AUTOSAR XML (schema 4-0-3)
standard types defined: Boolean, UInt16, UInt8
package /AUTOSAR_Platform/DataConstrs
  range DC_Boolean: raw 0..1
  range DC_UInt16: raw 0..65535
  range DC_UInt8: raw 0..255
package /PATAC/MSM/ComponentTypes
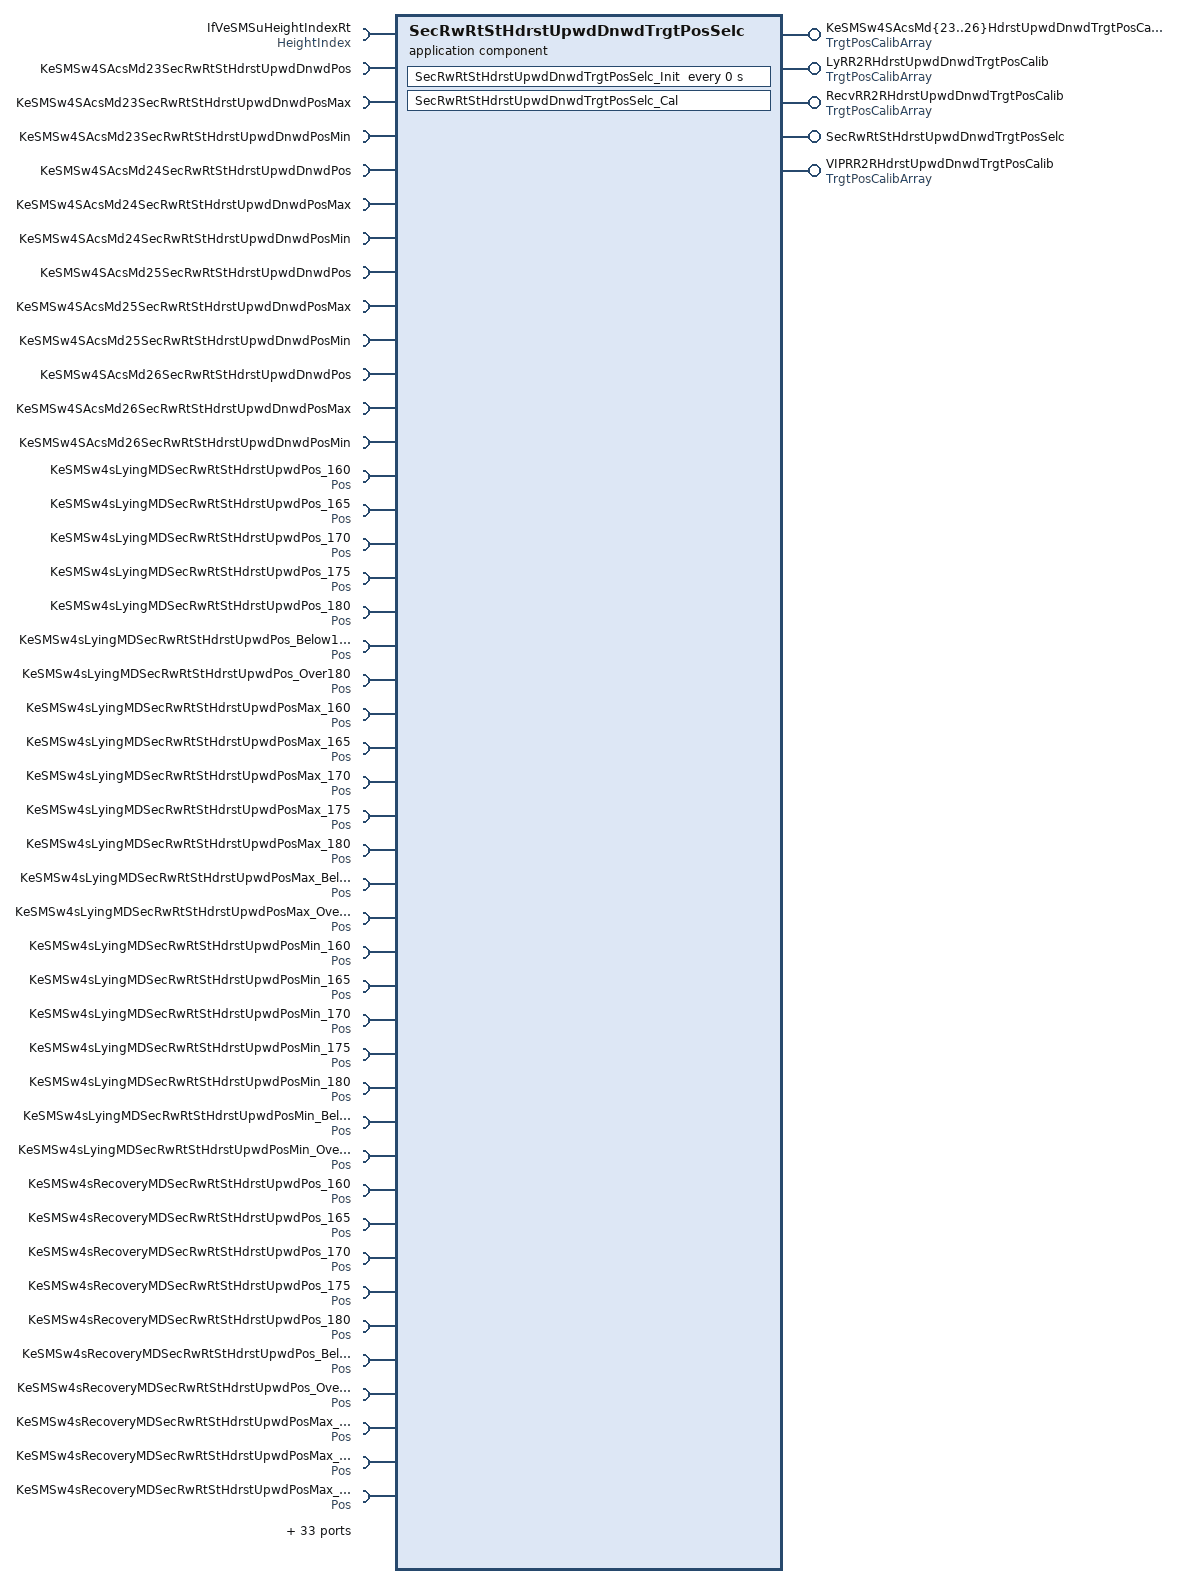
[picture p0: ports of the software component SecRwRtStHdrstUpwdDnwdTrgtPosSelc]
  application sw component type SecRwRtStHdrstUpwdDnwdTrgtPosSelc
    8 x provide port:
      KeSMSw4SAcsMd{23..26}HdrstUpwdDnwdTrgtPosCalib: nonqueued-sender-com-spec{data-element=TrgtPosArray, init-value=[4095, 4095, 4095]}, provided-interface=TrgtPosCalibArray
      LyRR2RHdrstUpwdDnwdTrgtPosCalib: nonqueued-sender-com-spec{data-element=TrgtPosArray, init-value=[4095, 4095, 4095]}, provided-interface=TrgtPosCalibArray
      RecvRR2RHdrstUpwdDnwdTrgtPosCalib: nonqueued-sender-com-spec{data-element=TrgtPosArray, init-value=[4095, 4095, 4095]}, provided-interface=TrgtPosCalibArray
      SecRwRtStHdrstUpwdDnwdTrgtPosSelc: server-com-spec{operation=Cal, queue-length=1}, provided-interface=SecRwRtStHdrstUpwdDnwdTrgtPosSelc
      VIPRR2RHdrstUpwdDnwdTrgtPosCalib: nonqueued-sender-com-spec{data-element=TrgtPosArray, init-value=[4095, 4095, 4095]}, provided-interface=TrgtPosCalibArray
    77 x require port:
      IfVeSMSuHeightIndexRt: nonqueued-receiver-com-spec{data-element=Val, filter=data-filter-type=ALWAYS, init-value=0}, required-interface=HeightIndex
      KeSMSw4SAcsMd23SecRwRtStHdrstUpwdDnwdPos: parameter-require-com-spec{init-value=0, parameter=KeSMSw4SAcsMd23SecRwRtStHdrstUpwdDnwdPos/Val}, required-interface=KeSMSw4SAcsMd23SecRwRtStHdrstUpwdDnwdPos
      KeSMSw4SAcsMd23SecRwRtStHdrstUpwdDnwdPosMax: parameter-require-com-spec{init-value=0, parameter=KeSMSw4SAcsMd23SecRwRtStHdrstUpwdDnwdPosMax/Val}, required-interface=KeSMSw4SAcsMd23SecRwRtStHdrstUpwdDnwdPosMax
      KeSMSw4SAcsMd23SecRwRtStHdrstUpwdDnwdPosMin: parameter-require-com-spec{init-value=0, parameter=KeSMSw4SAcsMd23SecRwRtStHdrstUpwdDnwdPosMin/Val}, required-interface=KeSMSw4SAcsMd23SecRwRtStHdrstUpwdDnwdPosMin
      KeSMSw4SAcsMd24SecRwRtStHdrstUpwdDnwdPos: parameter-require-com-spec{init-value=0, parameter=KeSMSw4SAcsMd24SecRwRtStHdrstUpwdDnwdPos/Val}, required-interface=KeSMSw4SAcsMd24SecRwRtStHdrstUpwdDnwdPos
      KeSMSw4SAcsMd24SecRwRtStHdrstUpwdDnwdPosMax: parameter-require-com-spec{init-value=0, parameter=KeSMSw4SAcsMd24SecRwRtStHdrstUpwdDnwdPosMax/Val}, required-interface=KeSMSw4SAcsMd24SecRwRtStHdrstUpwdDnwdPosMax
      KeSMSw4SAcsMd24SecRwRtStHdrstUpwdDnwdPosMin: parameter-require-com-spec{init-value=0, parameter=KeSMSw4SAcsMd24SecRwRtStHdrstUpwdDnwdPosMin/Val}, required-interface=KeSMSw4SAcsMd24SecRwRtStHdrstUpwdDnwdPosMin
      KeSMSw4SAcsMd25SecRwRtStHdrstUpwdDnwdPos: parameter-require-com-spec{init-value=0, parameter=KeSMSw4SAcsMd25SecRwRtStHdrstUpwdDnwdPos/Val}, required-interface=KeSMSw4SAcsMd25SecRwRtStHdrstUpwdDnwdPos
      KeSMSw4SAcsMd25SecRwRtStHdrstUpwdDnwdPosMax: parameter-require-com-spec{init-value=0, parameter=KeSMSw4SAcsMd25SecRwRtStHdrstUpwdDnwdPosMax/Val}, required-interface=KeSMSw4SAcsMd25SecRwRtStHdrstUpwdDnwdPosMax
      KeSMSw4SAcsMd25SecRwRtStHdrstUpwdDnwdPosMin: parameter-require-com-spec{init-value=0, parameter=KeSMSw4SAcsMd25SecRwRtStHdrstUpwdDnwdPosMin/Val}, required-interface=KeSMSw4SAcsMd25SecRwRtStHdrstUpwdDnwdPosMin
      KeSMSw4SAcsMd26SecRwRtStHdrstUpwdDnwdPos: parameter-require-com-spec{init-value=0, parameter=KeSMSw4SAcsMd26SecRwRtStHdrstUpwdDnwdPos/Val}, required-interface=KeSMSw4SAcsMd26SecRwRtStHdrstUpwdDnwdPos
      KeSMSw4SAcsMd26SecRwRtStHdrstUpwdDnwdPosMax: parameter-require-com-spec{init-value=0, parameter=KeSMSw4SAcsMd26SecRwRtStHdrstUpwdDnwdPosMax/Val}, required-interface=KeSMSw4SAcsMd26SecRwRtStHdrstUpwdDnwdPosMax
      KeSMSw4SAcsMd26SecRwRtStHdrstUpwdDnwdPosMin: parameter-require-com-spec{init-value=0, parameter=KeSMSw4SAcsMd26SecRwRtStHdrstUpwdDnwdPosMin/Val}, required-interface=KeSMSw4SAcsMd26SecRwRtStHdrstUpwdDnwdPosMin
      KeSMSw4sLyingMDSecRwRtStHdrstUpwdPos_160: parameter-require-com-spec{init-value=0, parameter=Pos/Val}, required-interface=Pos
      KeSMSw4sLyingMDSecRwRtStHdrstUpwdPos_165: parameter-require-com-spec{init-value=0, parameter=Pos/Val}, required-interface=Pos
      KeSMSw4sLyingMDSecRwRtStHdrstUpwdPos_170: parameter-require-com-spec{init-value=0, parameter=Pos/Val}, required-interface=Pos
      KeSMSw4sLyingMDSecRwRtStHdrstUpwdPos_175: parameter-require-com-spec{init-value=0, parameter=Pos/Val}, required-interface=Pos
      KeSMSw4sLyingMDSecRwRtStHdrstUpwdPos_180: parameter-require-com-spec{init-value=0, parameter=Pos/Val}, required-interface=Pos
      KeSMSw4sLyingMDSecRwRtStHdrstUpwdPos_Below160: parameter-require-com-spec{init-value=0, parameter=Pos/Val}, required-interface=Pos
      KeSMSw4sLyingMDSecRwRtStHdrstUpwdPos_Over180: parameter-require-com-spec{init-value=0, parameter=Pos/Val}, required-interface=Pos
      KeSMSw4sLyingMDSecRwRtStHdrstUpwdPosMax_160: parameter-require-com-spec{init-value=0, parameter=Pos/Val}, required-interface=Pos
      KeSMSw4sLyingMDSecRwRtStHdrstUpwdPosMax_165: parameter-require-com-spec{init-value=0, parameter=Pos/Val}, required-interface=Pos
      KeSMSw4sLyingMDSecRwRtStHdrstUpwdPosMax_170: parameter-require-com-spec{init-value=0, parameter=Pos/Val}, required-interface=Pos
      KeSMSw4sLyingMDSecRwRtStHdrstUpwdPosMax_175: parameter-require-com-spec{init-value=0, parameter=Pos/Val}, required-interface=Pos
      KeSMSw4sLyingMDSecRwRtStHdrstUpwdPosMax_180: parameter-require-com-spec{init-value=0, parameter=Pos/Val}, required-interface=Pos
      KeSMSw4sLyingMDSecRwRtStHdrstUpwdPosMax_Below160: parameter-require-com-spec{init-value=0, parameter=Pos/Val}, required-interface=Pos
      KeSMSw4sLyingMDSecRwRtStHdrstUpwdPosMax_Over180: parameter-require-com-spec{init-value=0, parameter=Pos/Val}, required-interface=Pos
      KeSMSw4sLyingMDSecRwRtStHdrstUpwdPosMin_160: parameter-require-com-spec{init-value=0, parameter=Pos/Val}, required-interface=Pos
      KeSMSw4sLyingMDSecRwRtStHdrstUpwdPosMin_165: parameter-require-com-spec{init-value=0, parameter=Pos/Val}, required-interface=Pos
      KeSMSw4sLyingMDSecRwRtStHdrstUpwdPosMin_170: parameter-require-com-spec{init-value=0, parameter=Pos/Val}, required-interface=Pos
      KeSMSw4sLyingMDSecRwRtStHdrstUpwdPosMin_175: parameter-require-com-spec{init-value=0, parameter=Pos/Val}, required-interface=Pos
      KeSMSw4sLyingMDSecRwRtStHdrstUpwdPosMin_180: parameter-require-com-spec{init-value=0, parameter=Pos/Val}, required-interface=Pos
      KeSMSw4sLyingMDSecRwRtStHdrstUpwdPosMin_Below160: parameter-require-com-spec{init-value=0, parameter=Pos/Val}, required-interface=Pos
      KeSMSw4sLyingMDSecRwRtStHdrstUpwdPosMin_Over180: parameter-require-com-spec{init-value=0, parameter=Pos/Val}, required-interface=Pos
      KeSMSw4sRecoveryMDSecRwRtStHdrstUpwdPos_160: parameter-require-com-spec{init-value=0, parameter=Pos/Val}, required-interface=Pos
      KeSMSw4sRecoveryMDSecRwRtStHdrstUpwdPos_165: parameter-require-com-spec{init-value=0, parameter=Pos/Val}, required-interface=Pos
      KeSMSw4sRecoveryMDSecRwRtStHdrstUpwdPos_170: parameter-require-com-spec{init-value=0, parameter=Pos/Val}, required-interface=Pos
      KeSMSw4sRecoveryMDSecRwRtStHdrstUpwdPos_175: parameter-require-com-spec{init-value=0, parameter=Pos/Val}, required-interface=Pos
      KeSMSw4sRecoveryMDSecRwRtStHdrstUpwdPos_180: parameter-require-com-spec{init-value=0, parameter=Pos/Val}, required-interface=Pos
      KeSMSw4sRecoveryMDSecRwRtStHdrstUpwdPos_Below160: parameter-require-com-spec{init-value=0, parameter=Pos/Val}, required-interface=Pos
      KeSMSw4sRecoveryMDSecRwRtStHdrstUpwdPos_Over180: parameter-require-com-spec{init-value=0, parameter=Pos/Val}, required-interface=Pos
      KeSMSw4sRecoveryMDSecRwRtStHdrstUpwdPosMax_160: parameter-require-com-spec{init-value=0, parameter=Pos/Val}, required-interface=Pos
      KeSMSw4sRecoveryMDSecRwRtStHdrstUpwdPosMax_165: parameter-require-com-spec{init-value=0, parameter=Pos/Val}, required-interface=Pos
      KeSMSw4sRecoveryMDSecRwRtStHdrstUpwdPosMax_170: parameter-require-com-spec{init-value=0, parameter=Pos/Val}, required-interface=Pos
      KeSMSw4sRecoveryMDSecRwRtStHdrstUpwdPosMax_175: parameter-require-com-spec{init-value=0, parameter=Pos/Val}, required-interface=Pos
      KeSMSw4sRecoveryMDSecRwRtStHdrstUpwdPosMax_180: parameter-require-com-spec{init-value=0, parameter=Pos/Val}, required-interface=Pos
      KeSMSw4sRecoveryMDSecRwRtStHdrstUpwdPosMax_Below160: parameter-require-com-spec{init-value=0, parameter=Pos/Val}, required-interface=Pos
      KeSMSw4sRecoveryMDSecRwRtStHdrstUpwdPosMax_Over180: parameter-require-com-spec{init-value=0, parameter=Pos/Val}, required-interface=Pos
      KeSMSw4sRecoveryMDSecRwRtStHdrstUpwdPosMin_160: parameter-require-com-spec{init-value=0, parameter=Pos/Val}, required-interface=Pos
      KeSMSw4sRecoveryMDSecRwRtStHdrstUpwdPosMin_165: parameter-require-com-spec{init-value=0, parameter=Pos/Val}, required-interface=Pos
      KeSMSw4sRecoveryMDSecRwRtStHdrstUpwdPosMin_170: parameter-require-com-spec{init-value=0, parameter=Pos/Val}, required-interface=Pos
      KeSMSw4sRecoveryMDSecRwRtStHdrstUpwdPosMin_175: parameter-require-com-spec{init-value=0, parameter=Pos/Val}, required-interface=Pos
      KeSMSw4sRecoveryMDSecRwRtStHdrstUpwdPosMin_180: parameter-require-com-spec{init-value=0, parameter=Pos/Val}, required-interface=Pos
      KeSMSw4sRecoveryMDSecRwRtStHdrstUpwdPosMin_Below160: parameter-require-com-spec{init-value=0, parameter=Pos/Val}, required-interface=Pos
      KeSMSw4sRecoveryMDSecRwRtStHdrstUpwdPosMin_Over180: parameter-require-com-spec{init-value=0, parameter=Pos/Val}, required-interface=Pos
      KeSMSw4sVIPMDSecRwRtStHdrstUpwdPos_160: parameter-require-com-spec{init-value=0, parameter=Pos/Val}, required-interface=Pos
      KeSMSw4sVIPMDSecRwRtStHdrstUpwdPos_165: parameter-require-com-spec{init-value=0, parameter=Pos/Val}, required-interface=Pos
      KeSMSw4sVIPMDSecRwRtStHdrstUpwdPos_170: parameter-require-com-spec{init-value=0, parameter=Pos/Val}, required-interface=Pos
      KeSMSw4sVIPMDSecRwRtStHdrstUpwdPos_175: parameter-require-com-spec{init-value=0, parameter=Pos/Val}, required-interface=Pos
      KeSMSw4sVIPMDSecRwRtStHdrstUpwdPos_180: parameter-require-com-spec{init-value=0, parameter=Pos/Val}, required-interface=Pos
      KeSMSw4sVIPMDSecRwRtStHdrstUpwdPos_Below160: parameter-require-com-spec{init-value=0, parameter=Pos/Val}, required-interface=Pos
      KeSMSw4sVIPMDSecRwRtStHdrstUpwdPos_Over180: parameter-require-com-spec{init-value=0, parameter=Pos/Val}, required-interface=Pos
      KeSMSw4sVIPMDSecRwRtStHdrstUpwdPosMax_160: parameter-require-com-spec{init-value=0, parameter=Pos/Val}, required-interface=Pos
      KeSMSw4sVIPMDSecRwRtStHdrstUpwdPosMax_165: parameter-require-com-spec{init-value=0, parameter=Pos/Val}, required-interface=Pos
      KeSMSw4sVIPMDSecRwRtStHdrstUpwdPosMax_170: parameter-require-com-spec{init-value=0, parameter=Pos/Val}, required-interface=Pos
      KeSMSw4sVIPMDSecRwRtStHdrstUpwdPosMax_175: parameter-require-com-spec{init-value=0, parameter=Pos/Val}, required-interface=Pos
      KeSMSw4sVIPMDSecRwRtStHdrstUpwdPosMax_180: parameter-require-com-spec{init-value=0, parameter=Pos/Val}, required-interface=Pos
      KeSMSw4sVIPMDSecRwRtStHdrstUpwdPosMax_Below160: parameter-require-com-spec{init-value=0, parameter=Pos/Val}, required-interface=Pos
      KeSMSw4sVIPMDSecRwRtStHdrstUpwdPosMax_Over180: parameter-require-com-spec{init-value=0, parameter=Pos/Val}, required-interface=Pos
      KeSMSw4sVIPMDSecRwRtStHdrstUpwdPosMin_160: parameter-require-com-spec{init-value=0, parameter=Pos/Val}, required-interface=Pos
      KeSMSw4sVIPMDSecRwRtStHdrstUpwdPosMin_165: parameter-require-com-spec{init-value=0, parameter=Pos/Val}, required-interface=Pos
      KeSMSw4sVIPMDSecRwRtStHdrstUpwdPosMin_170: parameter-require-com-spec{init-value=0, parameter=Pos/Val}, required-interface=Pos
      KeSMSw4sVIPMDSecRwRtStHdrstUpwdPosMin_175: parameter-require-com-spec{init-value=0, parameter=Pos/Val}, required-interface=Pos
      KeSMSw4sVIPMDSecRwRtStHdrstUpwdPosMin_180: parameter-require-com-spec{init-value=0, parameter=Pos/Val}, required-interface=Pos
      KeSMSw4sVIPMDSecRwRtStHdrstUpwdPosMin_Below160: parameter-require-com-spec{init-value=0, parameter=Pos/Val}, required-interface=Pos
      KeSMSw4sVIPMDSecRwRtStHdrstUpwdPosMin_Over180: parameter-require-com-spec{init-value=0, parameter=Pos/Val}, required-interface=Pos
      StNumFlg: required-interface=StNumFlg
        required-com-specs:
          data-element=Is4s, filter=data-filter-type=ALWAYS, init-value=0
          data-element=Is6s, filter=data-filter-type=ALWAYS, init-value=0
          data-element=Is6s7s, filter=data-filter-type=ALWAYS, init-value=0
          data-element=Is7s, filter=data-filter-type=ALWAYS, init-value=0
    behavior SecRwRtStHdrstUpwdDnwdTrgtPosSelc_InternalBehavior
      operation invoked event OIT_SecRwRtStHdrstUpwdDnwdTrgtPosSelc_Cal_SecRwRtStHdrstUpwdDnwdTrgtPosSelc_Cal: start-on-event=SecRwRtStHdrstUpwdDnwdTrgtPosSelc_Cal, operation=SecRwRtStHdrstUpwdDnwdTrgtPosSelc.Cal
      timing event SecRwRtStHdrstUpwdDnwdTrgtPosSelc_InitEvent: start-on-event=SecRwRtStHdrstUpwdDnwdTrgtPosSelc_Init, period=0
      runnable SecRwRtStHdrstUpwdDnwdTrgtPosSelc_Cal
        data-receive-point-by-arguments:
          5 x access:
            REC_IfVeSMSuHeightIndexRt_Val: accessed-variable=IfVeSMSuHeightIndexRt.Val
            REC_StNumFlg_Is4s: accessed-variable=StNumFlg.Is4s
            REC_StNumFlg_Is6s: accessed-variable=StNumFlg.Is6s
            REC_StNumFlg_Is6s7s: accessed-variable=StNumFlg.Is6s7s
            REC_StNumFlg_Is7s: accessed-variable=StNumFlg.Is7s
        data-send-points:
          7 x access:
            SEND_KeSMSw4SAcsMd{23..26}HdrstUpwdDnwdTrgtPosCalib_TrgtPosArray: accessed-variable=KeSMSw4SAcsMd{23..26}HdrstUpwdDnwdTrgtPosCalib.TrgtPosArray
            SEND_LyRR2RHdrstUpwdDnwdTrgtPosCalib_TrgtPosArray: accessed-variable=LyRR2RHdrstUpwdDnwdTrgtPosCalib.TrgtPosArray
            SEND_RecvRR2RHdrstUpwdDnwdTrgtPosCalib_TrgtPosArray: accessed-variable=RecvRR2RHdrstUpwdDnwdTrgtPosCalib.TrgtPosArray
            SEND_VIPRR2RHdrstUpwdDnwdTrgtPosCalib_TrgtPosArray: accessed-variable=VIPRR2RHdrstUpwdDnwdTrgtPosCalib.TrgtPosArray
        75 x parameter access:
          PA_KeSMSw4SAcsMd23SecRwRtStHdrstUpwdDnwdPos_Val: accessed-parameter=KeSMSw4SAcsMd23SecRwRtStHdrstUpwdDnwdPos.Val
          PA_KeSMSw4SAcsMd23SecRwRtStHdrstUpwdDnwdPosMax_Val: accessed-parameter=KeSMSw4SAcsMd23SecRwRtStHdrstUpwdDnwdPosMax.Val
          PA_KeSMSw4SAcsMd23SecRwRtStHdrstUpwdDnwdPosMin_Val: accessed-parameter=KeSMSw4SAcsMd23SecRwRtStHdrstUpwdDnwdPosMin.Val
          PA_KeSMSw4SAcsMd24SecRwRtStHdrstUpwdDnwdPos_Val: accessed-parameter=KeSMSw4SAcsMd24SecRwRtStHdrstUpwdDnwdPos.Val
          PA_KeSMSw4SAcsMd24SecRwRtStHdrstUpwdDnwdPosMax_Val: accessed-parameter=KeSMSw4SAcsMd24SecRwRtStHdrstUpwdDnwdPosMax.Val
          PA_KeSMSw4SAcsMd24SecRwRtStHdrstUpwdDnwdPosMin_Val: accessed-parameter=KeSMSw4SAcsMd24SecRwRtStHdrstUpwdDnwdPosMin.Val
          PA_KeSMSw4SAcsMd25SecRwRtStHdrstUpwdDnwdPos_Val: accessed-parameter=KeSMSw4SAcsMd25SecRwRtStHdrstUpwdDnwdPos.Val
          PA_KeSMSw4SAcsMd25SecRwRtStHdrstUpwdDnwdPosMax_Val: accessed-parameter=KeSMSw4SAcsMd25SecRwRtStHdrstUpwdDnwdPosMax.Val
          PA_KeSMSw4SAcsMd25SecRwRtStHdrstUpwdDnwdPosMin_Val: accessed-parameter=KeSMSw4SAcsMd25SecRwRtStHdrstUpwdDnwdPosMin.Val
          PA_KeSMSw4SAcsMd26SecRwRtStHdrstUpwdDnwdPos_Val: accessed-parameter=KeSMSw4SAcsMd26SecRwRtStHdrstUpwdDnwdPos.Val
          PA_KeSMSw4SAcsMd26SecRwRtStHdrstUpwdDnwdPosMax_Val: accessed-parameter=KeSMSw4SAcsMd26SecRwRtStHdrstUpwdDnwdPosMax.Val
          PA_KeSMSw4SAcsMd26SecRwRtStHdrstUpwdDnwdPosMin_Val: accessed-parameter=KeSMSw4SAcsMd26SecRwRtStHdrstUpwdDnwdPosMin.Val
          PA_KeSMSw4sLyingMDSecRwRtStHdrstUpwdPos_160_Val: accessed-parameter=KeSMSw4sLyingMDSecRwRtStHdrstUpwdPos_160.Val
          PA_KeSMSw4sLyingMDSecRwRtStHdrstUpwdPos_165_Val: accessed-parameter=KeSMSw4sLyingMDSecRwRtStHdrstUpwdPos_165.Val
          PA_KeSMSw4sLyingMDSecRwRtStHdrstUpwdPos_170_Val: accessed-parameter=KeSMSw4sLyingMDSecRwRtStHdrstUpwdPos_170.Val
          PA_KeSMSw4sLyingMDSecRwRtStHdrstUpwdPos_175_Val: accessed-parameter=KeSMSw4sLyingMDSecRwRtStHdrstUpwdPos_175.Val
          PA_KeSMSw4sLyingMDSecRwRtStHdrstUpwdPos_180_Val: accessed-parameter=KeSMSw4sLyingMDSecRwRtStHdrstUpwdPos_180.Val
          PA_KeSMSw4sLyingMDSecRwRtStHdrstUpwdPos_Below160_Val: accessed-parameter=KeSMSw4sLyingMDSecRwRtStHdrstUpwdPos_Below160.Val
          PA_KeSMSw4sLyingMDSecRwRtStHdrstUpwdPos_Over180_Val: accessed-parameter=KeSMSw4sLyingMDSecRwRtStHdrstUpwdPos_Over180.Val
          PA_KeSMSw4sLyingMDSecRwRtStHdrstUpwdPosMax_160_Val: accessed-parameter=KeSMSw4sLyingMDSecRwRtStHdrstUpwdPosMax_160.Val
          PA_KeSMSw4sLyingMDSecRwRtStHdrstUpwdPosMax_165_Val: accessed-parameter=KeSMSw4sLyingMDSecRwRtStHdrstUpwdPosMax_165.Val
          PA_KeSMSw4sLyingMDSecRwRtStHdrstUpwdPosMax_170_Val: accessed-parameter=KeSMSw4sLyingMDSecRwRtStHdrstUpwdPosMax_170.Val
          PA_KeSMSw4sLyingMDSecRwRtStHdrstUpwdPosMax_175_Val: accessed-parameter=KeSMSw4sLyingMDSecRwRtStHdrstUpwdPosMax_175.Val
          PA_KeSMSw4sLyingMDSecRwRtStHdrstUpwdPosMax_180_Val: accessed-parameter=KeSMSw4sLyingMDSecRwRtStHdrstUpwdPosMax_180.Val
          PA_KeSMSw4sLyingMDSecRwRtStHdrstUpwdPosMax_Below160_Val: accessed-parameter=KeSMSw4sLyingMDSecRwRtStHdrstUpwdPosMax_Below160.Val
          PA_KeSMSw4sLyingMDSecRwRtStHdrstUpwdPosMax_Over180_Val: accessed-parameter=KeSMSw4sLyingMDSecRwRtStHdrstUpwdPosMax_Over180.Val
          PA_KeSMSw4sLyingMDSecRwRtStHdrstUpwdPosMin_160_Val: accessed-parameter=KeSMSw4sLyingMDSecRwRtStHdrstUpwdPosMin_160.Val
          PA_KeSMSw4sLyingMDSecRwRtStHdrstUpwdPosMin_165_Val: accessed-parameter=KeSMSw4sLyingMDSecRwRtStHdrstUpwdPosMin_165.Val
          PA_KeSMSw4sLyingMDSecRwRtStHdrstUpwdPosMin_170_Val: accessed-parameter=KeSMSw4sLyingMDSecRwRtStHdrstUpwdPosMin_170.Val
          PA_KeSMSw4sLyingMDSecRwRtStHdrstUpwdPosMin_175_Val: accessed-parameter=KeSMSw4sLyingMDSecRwRtStHdrstUpwdPosMin_175.Val
          PA_KeSMSw4sLyingMDSecRwRtStHdrstUpwdPosMin_180_Val: accessed-parameter=KeSMSw4sLyingMDSecRwRtStHdrstUpwdPosMin_180.Val
          PA_KeSMSw4sLyingMDSecRwRtStHdrstUpwdPosMin_Below160_Val: accessed-parameter=KeSMSw4sLyingMDSecRwRtStHdrstUpwdPosMin_Below160.Val
          PA_KeSMSw4sLyingMDSecRwRtStHdrstUpwdPosMin_Over180_Val: accessed-parameter=KeSMSw4sLyingMDSecRwRtStHdrstUpwdPosMin_Over180.Val
          PA_KeSMSw4sRecoveryMDSecRwRtStHdrstUpwdPos_160_Val: accessed-parameter=KeSMSw4sRecoveryMDSecRwRtStHdrstUpwdPos_160.Val
          PA_KeSMSw4sRecoveryMDSecRwRtStHdrstUpwdPos_165_Val: accessed-parameter=KeSMSw4sRecoveryMDSecRwRtStHdrstUpwdPos_165.Val
          PA_KeSMSw4sRecoveryMDSecRwRtStHdrstUpwdPos_170_Val: accessed-parameter=KeSMSw4sRecoveryMDSecRwRtStHdrstUpwdPos_170.Val
          PA_KeSMSw4sRecoveryMDSecRwRtStHdrstUpwdPos_175_Val: accessed-parameter=KeSMSw4sRecoveryMDSecRwRtStHdrstUpwdPos_175.Val
          PA_KeSMSw4sRecoveryMDSecRwRtStHdrstUpwdPos_180_Val: accessed-parameter=KeSMSw4sRecoveryMDSecRwRtStHdrstUpwdPos_180.Val
          PA_KeSMSw4sRecoveryMDSecRwRtStHdrstUpwdPos_Below160_Val: accessed-parameter=KeSMSw4sRecoveryMDSecRwRtStHdrstUpwdPos_Below160.Val
          PA_KeSMSw4sRecoveryMDSecRwRtStHdrstUpwdPos_Over180_Val: accessed-parameter=KeSMSw4sRecoveryMDSecRwRtStHdrstUpwdPos_Over180.Val
          PA_KeSMSw4sRecoveryMDSecRwRtStHdrstUpwdPosMax_160_Val: accessed-parameter=KeSMSw4sRecoveryMDSecRwRtStHdrstUpwdPosMax_160.Val
          PA_KeSMSw4sRecoveryMDSecRwRtStHdrstUpwdPosMax_165_Val: accessed-parameter=KeSMSw4sRecoveryMDSecRwRtStHdrstUpwdPosMax_165.Val
          PA_KeSMSw4sRecoveryMDSecRwRtStHdrstUpwdPosMax_170_Val: accessed-parameter=KeSMSw4sRecoveryMDSecRwRtStHdrstUpwdPosMax_170.Val
          PA_KeSMSw4sRecoveryMDSecRwRtStHdrstUpwdPosMax_175_Val: accessed-parameter=KeSMSw4sRecoveryMDSecRwRtStHdrstUpwdPosMax_175.Val
          PA_KeSMSw4sRecoveryMDSecRwRtStHdrstUpwdPosMax_180_Val: accessed-parameter=KeSMSw4sRecoveryMDSecRwRtStHdrstUpwdPosMax_180.Val
          PA_KeSMSw4sRecoveryMDSecRwRtStHdrstUpwdPosMax_Below160_Val: accessed-parameter=KeSMSw4sRecoveryMDSecRwRtStHdrstUpwdPosMax_Below160.Val
          PA_KeSMSw4sRecoveryMDSecRwRtStHdrstUpwdPosMax_Over180_Val: accessed-parameter=KeSMSw4sRecoveryMDSecRwRtStHdrstUpwdPosMax_Over180.Val
          PA_KeSMSw4sRecoveryMDSecRwRtStHdrstUpwdPosMin_160_Val: accessed-parameter=KeSMSw4sRecoveryMDSecRwRtStHdrstUpwdPosMin_160.Val
          PA_KeSMSw4sRecoveryMDSecRwRtStHdrstUpwdPosMin_165_Val: accessed-parameter=KeSMSw4sRecoveryMDSecRwRtStHdrstUpwdPosMin_165.Val
          PA_KeSMSw4sRecoveryMDSecRwRtStHdrstUpwdPosMin_170_Val: accessed-parameter=KeSMSw4sRecoveryMDSecRwRtStHdrstUpwdPosMin_170.Val
          PA_KeSMSw4sRecoveryMDSecRwRtStHdrstUpwdPosMin_175_Val: accessed-parameter=KeSMSw4sRecoveryMDSecRwRtStHdrstUpwdPosMin_175.Val
          PA_KeSMSw4sRecoveryMDSecRwRtStHdrstUpwdPosMin_180_Val: accessed-parameter=KeSMSw4sRecoveryMDSecRwRtStHdrstUpwdPosMin_180.Val
          PA_KeSMSw4sRecoveryMDSecRwRtStHdrstUpwdPosMin_Below160_Val: accessed-parameter=KeSMSw4sRecoveryMDSecRwRtStHdrstUpwdPosMin_Below160.Val
          PA_KeSMSw4sRecoveryMDSecRwRtStHdrstUpwdPosMin_Over180_Val: accessed-parameter=KeSMSw4sRecoveryMDSecRwRtStHdrstUpwdPosMin_Over180.Val
          PA_KeSMSw4sVIPMDSecRwRtStHdrstUpwdPos_160_Val: accessed-parameter=KeSMSw4sVIPMDSecRwRtStHdrstUpwdPos_160.Val
          PA_KeSMSw4sVIPMDSecRwRtStHdrstUpwdPos_165_Val: accessed-parameter=KeSMSw4sVIPMDSecRwRtStHdrstUpwdPos_165.Val
          PA_KeSMSw4sVIPMDSecRwRtStHdrstUpwdPos_170_Val: accessed-parameter=KeSMSw4sVIPMDSecRwRtStHdrstUpwdPos_170.Val
          PA_KeSMSw4sVIPMDSecRwRtStHdrstUpwdPos_175_Val: accessed-parameter=KeSMSw4sVIPMDSecRwRtStHdrstUpwdPos_175.Val
          PA_KeSMSw4sVIPMDSecRwRtStHdrstUpwdPos_180_Val: accessed-parameter=KeSMSw4sVIPMDSecRwRtStHdrstUpwdPos_180.Val
          PA_KeSMSw4sVIPMDSecRwRtStHdrstUpwdPos_Below160_Val: accessed-parameter=KeSMSw4sVIPMDSecRwRtStHdrstUpwdPos_Below160.Val
          PA_KeSMSw4sVIPMDSecRwRtStHdrstUpwdPos_Over180_Val: accessed-parameter=KeSMSw4sVIPMDSecRwRtStHdrstUpwdPos_Over180.Val
          PA_KeSMSw4sVIPMDSecRwRtStHdrstUpwdPosMax_160_Val: accessed-parameter=KeSMSw4sVIPMDSecRwRtStHdrstUpwdPosMax_160.Val
          PA_KeSMSw4sVIPMDSecRwRtStHdrstUpwdPosMax_165_Val: accessed-parameter=KeSMSw4sVIPMDSecRwRtStHdrstUpwdPosMax_165.Val
          PA_KeSMSw4sVIPMDSecRwRtStHdrstUpwdPosMax_170_Val: accessed-parameter=KeSMSw4sVIPMDSecRwRtStHdrstUpwdPosMax_170.Val
          PA_KeSMSw4sVIPMDSecRwRtStHdrstUpwdPosMax_175_Val: accessed-parameter=KeSMSw4sVIPMDSecRwRtStHdrstUpwdPosMax_175.Val
          PA_KeSMSw4sVIPMDSecRwRtStHdrstUpwdPosMax_180_Val: accessed-parameter=KeSMSw4sVIPMDSecRwRtStHdrstUpwdPosMax_180.Val
          PA_KeSMSw4sVIPMDSecRwRtStHdrstUpwdPosMax_Below160_Val: accessed-parameter=KeSMSw4sVIPMDSecRwRtStHdrstUpwdPosMax_Below160.Val
          PA_KeSMSw4sVIPMDSecRwRtStHdrstUpwdPosMax_Over180_Val: accessed-parameter=KeSMSw4sVIPMDSecRwRtStHdrstUpwdPosMax_Over180.Val
          PA_KeSMSw4sVIPMDSecRwRtStHdrstUpwdPosMin_160_Val: accessed-parameter=KeSMSw4sVIPMDSecRwRtStHdrstUpwdPosMin_160.Val
          PA_KeSMSw4sVIPMDSecRwRtStHdrstUpwdPosMin_165_Val: accessed-parameter=KeSMSw4sVIPMDSecRwRtStHdrstUpwdPosMin_165.Val
          PA_KeSMSw4sVIPMDSecRwRtStHdrstUpwdPosMin_170_Val: accessed-parameter=KeSMSw4sVIPMDSecRwRtStHdrstUpwdPosMin_170.Val
          PA_KeSMSw4sVIPMDSecRwRtStHdrstUpwdPosMin_175_Val: accessed-parameter=KeSMSw4sVIPMDSecRwRtStHdrstUpwdPosMin_175.Val
          PA_KeSMSw4sVIPMDSecRwRtStHdrstUpwdPosMin_180_Val: accessed-parameter=KeSMSw4sVIPMDSecRwRtStHdrstUpwdPosMin_180.Val
          PA_KeSMSw4sVIPMDSecRwRtStHdrstUpwdPosMin_Below160_Val: accessed-parameter=KeSMSw4sVIPMDSecRwRtStHdrstUpwdPosMin_Below160.Val
          PA_KeSMSw4sVIPMDSecRwRtStHdrstUpwdPosMin_Over180_Val: accessed-parameter=KeSMSw4sVIPMDSecRwRtStHdrstUpwdPosMin_Over180.Val
      runnable SecRwRtStHdrstUpwdDnwdTrgtPosSelc_Init
        75 x parameter access:
          PA_KeSMSw4SAcsMd23SecRwRtStHdrstUpwdDnwdPos_Val: accessed-parameter=KeSMSw4SAcsMd23SecRwRtStHdrstUpwdDnwdPos.Val
          PA_KeSMSw4SAcsMd23SecRwRtStHdrstUpwdDnwdPosMax_Val: accessed-parameter=KeSMSw4SAcsMd23SecRwRtStHdrstUpwdDnwdPosMax.Val
          PA_KeSMSw4SAcsMd23SecRwRtStHdrstUpwdDnwdPosMin_Val: accessed-parameter=KeSMSw4SAcsMd23SecRwRtStHdrstUpwdDnwdPosMin.Val
          PA_KeSMSw4SAcsMd24SecRwRtStHdrstUpwdDnwdPos_Val: accessed-parameter=KeSMSw4SAcsMd24SecRwRtStHdrstUpwdDnwdPos.Val
          PA_KeSMSw4SAcsMd24SecRwRtStHdrstUpwdDnwdPosMax_Val: accessed-parameter=KeSMSw4SAcsMd24SecRwRtStHdrstUpwdDnwdPosMax.Val
          PA_KeSMSw4SAcsMd24SecRwRtStHdrstUpwdDnwdPosMin_Val: accessed-parameter=KeSMSw4SAcsMd24SecRwRtStHdrstUpwdDnwdPosMin.Val
          PA_KeSMSw4SAcsMd25SecRwRtStHdrstUpwdDnwdPos_Val: accessed-parameter=KeSMSw4SAcsMd25SecRwRtStHdrstUpwdDnwdPos.Val
          PA_KeSMSw4SAcsMd25SecRwRtStHdrstUpwdDnwdPosMax_Val: accessed-parameter=KeSMSw4SAcsMd25SecRwRtStHdrstUpwdDnwdPosMax.Val
          PA_KeSMSw4SAcsMd25SecRwRtStHdrstUpwdDnwdPosMin_Val: accessed-parameter=KeSMSw4SAcsMd25SecRwRtStHdrstUpwdDnwdPosMin.Val
          PA_KeSMSw4SAcsMd26SecRwRtStHdrstUpwdDnwdPos_Val: accessed-parameter=KeSMSw4SAcsMd26SecRwRtStHdrstUpwdDnwdPos.Val
          PA_KeSMSw4SAcsMd26SecRwRtStHdrstUpwdDnwdPosMax_Val: accessed-parameter=KeSMSw4SAcsMd26SecRwRtStHdrstUpwdDnwdPosMax.Val
          PA_KeSMSw4SAcsMd26SecRwRtStHdrstUpwdDnwdPosMin_Val: accessed-parameter=KeSMSw4SAcsMd26SecRwRtStHdrstUpwdDnwdPosMin.Val
          PA_KeSMSw4sLyingMDSecRwRtStHdrstUpwdPos_160_Val: accessed-parameter=KeSMSw4sLyingMDSecRwRtStHdrstUpwdPos_160.Val
          PA_KeSMSw4sLyingMDSecRwRtStHdrstUpwdPos_165_Val: accessed-parameter=KeSMSw4sLyingMDSecRwRtStHdrstUpwdPos_165.Val
          PA_KeSMSw4sLyingMDSecRwRtStHdrstUpwdPos_170_Val: accessed-parameter=KeSMSw4sLyingMDSecRwRtStHdrstUpwdPos_170.Val
          PA_KeSMSw4sLyingMDSecRwRtStHdrstUpwdPos_175_Val: accessed-parameter=KeSMSw4sLyingMDSecRwRtStHdrstUpwdPos_175.Val
          PA_KeSMSw4sLyingMDSecRwRtStHdrstUpwdPos_180_Val: accessed-parameter=KeSMSw4sLyingMDSecRwRtStHdrstUpwdPos_180.Val
          PA_KeSMSw4sLyingMDSecRwRtStHdrstUpwdPos_Below160_Val: accessed-parameter=KeSMSw4sLyingMDSecRwRtStHdrstUpwdPos_Below160.Val
          PA_KeSMSw4sLyingMDSecRwRtStHdrstUpwdPos_Over180_Val: accessed-parameter=KeSMSw4sLyingMDSecRwRtStHdrstUpwdPos_Over180.Val
          PA_KeSMSw4sLyingMDSecRwRtStHdrstUpwdPosMax_160_Val: accessed-parameter=KeSMSw4sLyingMDSecRwRtStHdrstUpwdPosMax_160.Val
          PA_KeSMSw4sLyingMDSecRwRtStHdrstUpwdPosMax_165_Val: accessed-parameter=KeSMSw4sLyingMDSecRwRtStHdrstUpwdPosMax_165.Val
          PA_KeSMSw4sLyingMDSecRwRtStHdrstUpwdPosMax_170_Val: accessed-parameter=KeSMSw4sLyingMDSecRwRtStHdrstUpwdPosMax_170.Val
          PA_KeSMSw4sLyingMDSecRwRtStHdrstUpwdPosMax_175_Val: accessed-parameter=KeSMSw4sLyingMDSecRwRtStHdrstUpwdPosMax_175.Val
          PA_KeSMSw4sLyingMDSecRwRtStHdrstUpwdPosMax_180_Val: accessed-parameter=KeSMSw4sLyingMDSecRwRtStHdrstUpwdPosMax_180.Val
          PA_KeSMSw4sLyingMDSecRwRtStHdrstUpwdPosMax_Below160_Val: accessed-parameter=KeSMSw4sLyingMDSecRwRtStHdrstUpwdPosMax_Below160.Val
          PA_KeSMSw4sLyingMDSecRwRtStHdrstUpwdPosMax_Over180_Val: accessed-parameter=KeSMSw4sLyingMDSecRwRtStHdrstUpwdPosMax_Over180.Val
          PA_KeSMSw4sLyingMDSecRwRtStHdrstUpwdPosMin_160_Val: accessed-parameter=KeSMSw4sLyingMDSecRwRtStHdrstUpwdPosMin_160.Val
          PA_KeSMSw4sLyingMDSecRwRtStHdrstUpwdPosMin_165_Val: accessed-parameter=KeSMSw4sLyingMDSecRwRtStHdrstUpwdPosMin_165.Val
          PA_KeSMSw4sLyingMDSecRwRtStHdrstUpwdPosMin_170_Val: accessed-parameter=KeSMSw4sLyingMDSecRwRtStHdrstUpwdPosMin_170.Val
          PA_KeSMSw4sLyingMDSecRwRtStHdrstUpwdPosMin_175_Val: accessed-parameter=KeSMSw4sLyingMDSecRwRtStHdrstUpwdPosMin_175.Val
          PA_KeSMSw4sLyingMDSecRwRtStHdrstUpwdPosMin_180_Val: accessed-parameter=KeSMSw4sLyingMDSecRwRtStHdrstUpwdPosMin_180.Val
          PA_KeSMSw4sLyingMDSecRwRtStHdrstUpwdPosMin_Below160_Val: accessed-parameter=KeSMSw4sLyingMDSecRwRtStHdrstUpwdPosMin_Below160.Val
          PA_KeSMSw4sLyingMDSecRwRtStHdrstUpwdPosMin_Over180_Val: accessed-parameter=KeSMSw4sLyingMDSecRwRtStHdrstUpwdPosMin_Over180.Val
          PA_KeSMSw4sRecoveryMDSecRwRtStHdrstUpwdPos_160_Val: accessed-parameter=KeSMSw4sRecoveryMDSecRwRtStHdrstUpwdPos_160.Val
          PA_KeSMSw4sRecoveryMDSecRwRtStHdrstUpwdPos_165_Val: accessed-parameter=KeSMSw4sRecoveryMDSecRwRtStHdrstUpwdPos_165.Val
          PA_KeSMSw4sRecoveryMDSecRwRtStHdrstUpwdPos_170_Val: accessed-parameter=KeSMSw4sRecoveryMDSecRwRtStHdrstUpwdPos_170.Val
          PA_KeSMSw4sRecoveryMDSecRwRtStHdrstUpwdPos_175_Val: accessed-parameter=KeSMSw4sRecoveryMDSecRwRtStHdrstUpwdPos_175.Val
          PA_KeSMSw4sRecoveryMDSecRwRtStHdrstUpwdPos_180_Val: accessed-parameter=KeSMSw4sRecoveryMDSecRwRtStHdrstUpwdPos_180.Val
          PA_KeSMSw4sRecoveryMDSecRwRtStHdrstUpwdPos_Below160_Val: accessed-parameter=KeSMSw4sRecoveryMDSecRwRtStHdrstUpwdPos_Below160.Val
          PA_KeSMSw4sRecoveryMDSecRwRtStHdrstUpwdPos_Over180_Val: accessed-parameter=KeSMSw4sRecoveryMDSecRwRtStHdrstUpwdPos_Over180.Val
          PA_KeSMSw4sRecoveryMDSecRwRtStHdrstUpwdPosMax_160_Val: accessed-parameter=KeSMSw4sRecoveryMDSecRwRtStHdrstUpwdPosMax_160.Val
          PA_KeSMSw4sRecoveryMDSecRwRtStHdrstUpwdPosMax_165_Val: accessed-parameter=KeSMSw4sRecoveryMDSecRwRtStHdrstUpwdPosMax_165.Val
          PA_KeSMSw4sRecoveryMDSecRwRtStHdrstUpwdPosMax_170_Val: accessed-parameter=KeSMSw4sRecoveryMDSecRwRtStHdrstUpwdPosMax_170.Val
          PA_KeSMSw4sRecoveryMDSecRwRtStHdrstUpwdPosMax_175_Val: accessed-parameter=KeSMSw4sRecoveryMDSecRwRtStHdrstUpwdPosMax_175.Val
          PA_KeSMSw4sRecoveryMDSecRwRtStHdrstUpwdPosMax_180_Val: accessed-parameter=KeSMSw4sRecoveryMDSecRwRtStHdrstUpwdPosMax_180.Val
          PA_KeSMSw4sRecoveryMDSecRwRtStHdrstUpwdPosMax_Below160_Val: accessed-parameter=KeSMSw4sRecoveryMDSecRwRtStHdrstUpwdPosMax_Below160.Val
          PA_KeSMSw4sRecoveryMDSecRwRtStHdrstUpwdPosMax_Over180_Val: accessed-parameter=KeSMSw4sRecoveryMDSecRwRtStHdrstUpwdPosMax_Over180.Val
          PA_KeSMSw4sRecoveryMDSecRwRtStHdrstUpwdPosMin_160_Val: accessed-parameter=KeSMSw4sRecoveryMDSecRwRtStHdrstUpwdPosMin_160.Val
          PA_KeSMSw4sRecoveryMDSecRwRtStHdrstUpwdPosMin_165_Val: accessed-parameter=KeSMSw4sRecoveryMDSecRwRtStHdrstUpwdPosMin_165.Val
          PA_KeSMSw4sRecoveryMDSecRwRtStHdrstUpwdPosMin_170_Val: accessed-parameter=KeSMSw4sRecoveryMDSecRwRtStHdrstUpwdPosMin_170.Val
          PA_KeSMSw4sRecoveryMDSecRwRtStHdrstUpwdPosMin_175_Val: accessed-parameter=KeSMSw4sRecoveryMDSecRwRtStHdrstUpwdPosMin_175.Val
          PA_KeSMSw4sRecoveryMDSecRwRtStHdrstUpwdPosMin_180_Val: accessed-parameter=KeSMSw4sRecoveryMDSecRwRtStHdrstUpwdPosMin_180.Val
          PA_KeSMSw4sRecoveryMDSecRwRtStHdrstUpwdPosMin_Below160_Val: accessed-parameter=KeSMSw4sRecoveryMDSecRwRtStHdrstUpwdPosMin_Below160.Val
          PA_KeSMSw4sRecoveryMDSecRwRtStHdrstUpwdPosMin_Over180_Val: accessed-parameter=KeSMSw4sRecoveryMDSecRwRtStHdrstUpwdPosMin_Over180.Val
          PA_KeSMSw4sVIPMDSecRwRtStHdrstUpwdPos_160_Val: accessed-parameter=KeSMSw4sVIPMDSecRwRtStHdrstUpwdPos_160.Val
          PA_KeSMSw4sVIPMDSecRwRtStHdrstUpwdPos_165_Val: accessed-parameter=KeSMSw4sVIPMDSecRwRtStHdrstUpwdPos_165.Val
          PA_KeSMSw4sVIPMDSecRwRtStHdrstUpwdPos_170_Val: accessed-parameter=KeSMSw4sVIPMDSecRwRtStHdrstUpwdPos_170.Val
          PA_KeSMSw4sVIPMDSecRwRtStHdrstUpwdPos_175_Val: accessed-parameter=KeSMSw4sVIPMDSecRwRtStHdrstUpwdPos_175.Val
          PA_KeSMSw4sVIPMDSecRwRtStHdrstUpwdPos_180_Val: accessed-parameter=KeSMSw4sVIPMDSecRwRtStHdrstUpwdPos_180.Val
          PA_KeSMSw4sVIPMDSecRwRtStHdrstUpwdPos_Below160_Val: accessed-parameter=KeSMSw4sVIPMDSecRwRtStHdrstUpwdPos_Below160.Val
          PA_KeSMSw4sVIPMDSecRwRtStHdrstUpwdPos_Over180_Val: accessed-parameter=KeSMSw4sVIPMDSecRwRtStHdrstUpwdPos_Over180.Val
          PA_KeSMSw4sVIPMDSecRwRtStHdrstUpwdPosMax_160_Val: accessed-parameter=KeSMSw4sVIPMDSecRwRtStHdrstUpwdPosMax_160.Val
          PA_KeSMSw4sVIPMDSecRwRtStHdrstUpwdPosMax_165_Val: accessed-parameter=KeSMSw4sVIPMDSecRwRtStHdrstUpwdPosMax_165.Val
          PA_KeSMSw4sVIPMDSecRwRtStHdrstUpwdPosMax_170_Val: accessed-parameter=KeSMSw4sVIPMDSecRwRtStHdrstUpwdPosMax_170.Val
          PA_KeSMSw4sVIPMDSecRwRtStHdrstUpwdPosMax_175_Val: accessed-parameter=KeSMSw4sVIPMDSecRwRtStHdrstUpwdPosMax_175.Val
          PA_KeSMSw4sVIPMDSecRwRtStHdrstUpwdPosMax_180_Val: accessed-parameter=KeSMSw4sVIPMDSecRwRtStHdrstUpwdPosMax_180.Val
          PA_KeSMSw4sVIPMDSecRwRtStHdrstUpwdPosMax_Below160_Val: accessed-parameter=KeSMSw4sVIPMDSecRwRtStHdrstUpwdPosMax_Below160.Val
          PA_KeSMSw4sVIPMDSecRwRtStHdrstUpwdPosMax_Over180_Val: accessed-parameter=KeSMSw4sVIPMDSecRwRtStHdrstUpwdPosMax_Over180.Val
          PA_KeSMSw4sVIPMDSecRwRtStHdrstUpwdPosMin_160_Val: accessed-parameter=KeSMSw4sVIPMDSecRwRtStHdrstUpwdPosMin_160.Val
          PA_KeSMSw4sVIPMDSecRwRtStHdrstUpwdPosMin_165_Val: accessed-parameter=KeSMSw4sVIPMDSecRwRtStHdrstUpwdPosMin_165.Val
          PA_KeSMSw4sVIPMDSecRwRtStHdrstUpwdPosMin_170_Val: accessed-parameter=KeSMSw4sVIPMDSecRwRtStHdrstUpwdPosMin_170.Val
          PA_KeSMSw4sVIPMDSecRwRtStHdrstUpwdPosMin_175_Val: accessed-parameter=KeSMSw4sVIPMDSecRwRtStHdrstUpwdPosMin_175.Val
          PA_KeSMSw4sVIPMDSecRwRtStHdrstUpwdPosMin_180_Val: accessed-parameter=KeSMSw4sVIPMDSecRwRtStHdrstUpwdPosMin_180.Val
          PA_KeSMSw4sVIPMDSecRwRtStHdrstUpwdPosMin_Below160_Val: accessed-parameter=KeSMSw4sVIPMDSecRwRtStHdrstUpwdPosMin_Below160.Val
          PA_KeSMSw4sVIPMDSecRwRtStHdrstUpwdPosMin_Over180_Val: accessed-parameter=KeSMSw4sVIPMDSecRwRtStHdrstUpwdPosMin_Over180.Val
  swc implementation SecRwRtStHdrstUpwdDnwdTrgtPosSelc_Implementation: behavior=SecRwRtStHdrstUpwdDnwdTrgtPosSelc_InternalBehavior
    code-descriptors:
      code Default: artifact-descriptors=autosar-engineering-object={short-label=Default, category=SWSRC}
package /PATAC/MSM/ModeAdjust/CalPortInterface
  13 x parameter interface:
    KeSMSw4SAcsMd23SecRwRtStHdrstUpwdDnwdPos
      parameter data prototype Val: sw-calibration-access=READ-WRITE, type=UInt16
    KeSMSw4SAcsMd23SecRwRtStHdrstUpwdDnwdPosMax
      parameter data prototype Val: sw-calibration-access=READ-WRITE, type=UInt16
    KeSMSw4SAcsMd23SecRwRtStHdrstUpwdDnwdPosMin
      parameter data prototype Val: sw-calibration-access=READ-WRITE, type=UInt16
    KeSMSw4SAcsMd24SecRwRtStHdrstUpwdDnwdPos
      parameter data prototype Val: sw-calibration-access=READ-WRITE, type=UInt16
    KeSMSw4SAcsMd24SecRwRtStHdrstUpwdDnwdPosMax
      parameter data prototype Val: sw-calibration-access=READ-WRITE, type=UInt16
    KeSMSw4SAcsMd24SecRwRtStHdrstUpwdDnwdPosMin
      parameter data prototype Val: sw-calibration-access=READ-WRITE, type=UInt16
    KeSMSw4SAcsMd25SecRwRtStHdrstUpwdDnwdPos
      parameter data prototype Val: sw-calibration-access=READ-WRITE, type=UInt16
    KeSMSw4SAcsMd25SecRwRtStHdrstUpwdDnwdPosMax
      parameter data prototype Val: sw-calibration-access=READ-WRITE, type=UInt16
    KeSMSw4SAcsMd25SecRwRtStHdrstUpwdDnwdPosMin
      parameter data prototype Val: sw-calibration-access=READ-WRITE, type=UInt16
    KeSMSw4SAcsMd26SecRwRtStHdrstUpwdDnwdPos
      parameter data prototype Val: sw-calibration-access=READ-WRITE, type=UInt16
    KeSMSw4SAcsMd26SecRwRtStHdrstUpwdDnwdPosMax
      parameter data prototype Val: sw-calibration-access=READ-WRITE, type=UInt16
    KeSMSw4SAcsMd26SecRwRtStHdrstUpwdDnwdPosMin
      parameter data prototype Val: sw-calibration-access=READ-WRITE, type=UInt16
    Pos
      parameter data prototype Val: sw-calibration-access=READ-WRITE, type=UInt16
package /PATAC/MSM/ModeAdjust/DataType
  impl type TrgtPosCalibArray: category=ARRAY, sw-calibration-access=READ-ONLY, type-emitter=RTE  # 0:pos 1:max 2:min
    element Element: array-size=3, array-size-semantics=FIXED-SIZE, implementation-data-type=UInt16, invalid-value=0
package /PATAC/MSM/ModeAdjust/PortInterface
  client server interface SecRwRtStHdrstUpwdDnwdTrgtPosSelc
    operation Cal
  sender receiver interface HeightIndex: invalidation-policy{data-element=Val, handle-invalid=DONT-INVALIDATE}
    data Val: type=UInt8  # 0：under 160 1：160 2：165 3：170 4：175 5：180 6：over 180
  sender receiver interface StNumFlg
    4 x data, all with type=Boolean:
      Is4s
      Is6s
      Is6s7s
      Is7s
    invalidation-policys:
      data-element=Is7s, handle-invalid=DONT-INVALIDATE
      data-element=Is6s, handle-invalid=DONT-INVALIDATE
      data-element=Is4s, handle-invalid=DONT-INVALIDATE
      data-element=Is6s7s, handle-invalid=DONT-INVALIDATE
  sender receiver interface TrgtPosCalibArray: invalidation-policy{data-element=TrgtPosArray, handle-invalid=DONT-INVALIDATE}
    data TrgtPosArray: type=TrgtPosCalibArray  # 0:Pos 1:Max 2:Min
